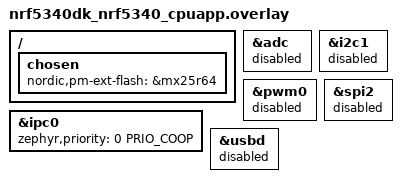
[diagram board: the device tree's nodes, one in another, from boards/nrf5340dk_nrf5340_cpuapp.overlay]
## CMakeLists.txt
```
#
# Copyright (c) 2023 Nordic Semiconductor ASA
#
# SPDX-License-Identifier: LicenseRef-Nordic-5-Clause
#

cmake_minimum_required(VERSION 3.20.0)

find_package(Zephyr HINTS $ENV{ZEPHYR_BASE})

project(matter-bridge)

# Enable GNU STD support.
include(${ZEPHYR_CONNECTEDHOMEIP_MODULE_DIR}/config/nrfconnect/app/enable-gnu-std.cmake)

# NORDIC SDK APP START

# Include all source files that are located in the Matter common directory.
include(${ZEPHYR_NRF_MODULE_DIR}/samples/matter/common/cmake/source_common.cmake)

# Include Data Model utils
include(${ZEPHYR_NRF_MODULE_DIR}/samples/matter/common/cmake/data_model.cmake)

include(${ZEPHYR_NRF_MODULE_DIR}/samples/matter/common/cmake/zap_helpers.cmake)
ncs_get_zap_parent_dir(ZAP_PARENT_DIR)

target_include_directories(app PRIVATE
    src
    src/bridged_device_types
    ${ZAP_PARENT_DIR}
    ${ZEPHYR_NRF_MODULE_DIR}/samples/matter/common/src/bridge/
    ${ZEPHYR_NRF_MODULE_DIR}/samples/matter/common/src/bridge/util
)

target_sources(app PRIVATE
    src/app_task.cpp
    src/main.cpp
    src/bridge_shell.cpp
    src/zcl_callbacks.cpp
    ${ZEPHYR_NRF_MODULE_DIR}/samples/matter/common/src/bridge/bridge_manager.cpp
    ${ZEPHYR_NRF_MODULE_DIR}/samples/matter/common/src/bridge/matter_bridged_device.cpp
    ${ZEPHYR_NRF_MODULE_DIR}/samples/matter/common/src/bridge/bridge_storage_manager.cpp
    ${ZEPHYR_NRF_MODULE_DIR}/samples/matter/common/src/bridge/bridged_device_data_provider.cpp
    ${ZEPHYR_NRF_MODULE_DIR}/samples/matter/common/src/binding/binding_handler.cpp
)

if(CONFIG_BRIDGED_DEVICE_BT)
    target_sources(app PRIVATE
         ${ZEPHYR_NRF_MODULE_DIR}/samples/matter/common/src/bridge/ble_connectivity_manager.cpp
        src/ble_providers/ble_bridged_device_factory.cpp
    )
    target_include_directories(app PRIVATE src/ble_providers)

if(CONFIG_BRIDGE_ONOFF_LIGHT_BRIDGED_DEVICE AND (CONFIG_BRIDGE_GENERIC_SWITCH_BRIDGED_DEVICE OR CONFIG_BRIDGE_ONOFF_LIGHT_SWITCH_BRIDGED_DEVICE))
    target_sources(app PRIVATE
        src/bridged_device_types/onoff_light.cpp
        src/ble_providers/ble_lbs_data_provider.cpp
    )

if(CONFIG_BRIDGE_GENERIC_SWITCH_BRIDGED_DEVICE)
    target_sources(app PRIVATE src/bridged_device_types/generic_switch.cpp)
endif()

if(CONFIG_BRIDGE_ONOFF_LIGHT_SWITCH_BRIDGED_DEVICE)
    target_sources(app PRIVATE
        src/bridged_device_types/onoff_light_switch.cpp
    )
endif()

endif() # CONFIG_BRIDGE_ONOFF_LIGHT_BRIDGED_DEVICE AND (CONFIG_BRIDGE_GENERIC_SWITCH_BRIDGED_DEVICE OR CONFIG_BRIDGE_ONOFF_LIGHT_SWITCH_BRIDGED_DEVICE)

if(CONFIG_BRIDGE_HUMIDITY_SENSOR_BRIDGED_DEVICE)
    target_sources(app PRIVATE
        src/bridged_device_types/humidity_sensor.cpp
    )
endif() # CONFIG_BRIDGE_HUMIDITY_SENSOR_BRIDGED_DEVICE

if(CONFIG_BRIDGE_TEMPERATURE_SENSOR_BRIDGED_DEVICE)
    target_sources(app PRIVATE
        src/bridged_device_types/temperature_sensor.cpp
    )
endif() # CONFIG_BRIDGE_TEMPERATURE_SENSOR_BRIDGED_DEVICE

# Assume it makes no sense to support BLE environmental sensor without all Matter counterparts
if(CONFIG_BRIDGE_TEMPERATURE_SENSOR_BRIDGED_DEVICE AND CONFIG_BRIDGE_HUMIDITY_SENSOR_BRIDGED_DEVICE)
    target_sources(app PRIVATE
        src/ble_providers/ble_environmental_data_provider.cpp
    )
endif() # CONFIG_BRIDGE_TEMPERATURE_SENSOR_BRIDGED_DEVICE AND CONFIG_BRIDGE_HUMIDITY_SENSOR_BRIDGED_DEVICE

else()
    target_sources(app PRIVATE
        src/simulated_providers/simulated_bridged_device_factory.cpp
    )
    target_include_directories(app PRIVATE src/simulated_providers)

if(CONFIG_BRIDGE_ONOFF_LIGHT_BRIDGED_DEVICE AND (CONFIG_BRIDGE_GENERIC_SWITCH_BRIDGED_DEVICE OR CONFIG_BRIDGE_ONOFF_LIGHT_SWITCH_BRIDGED_DEVICE))
    target_sources(app PRIVATE
        src/bridged_device_types/onoff_light.cpp
        src/simulated_providers/simulated_onoff_light_data_provider.cpp
    )

if(CONFIG_BRIDGE_GENERIC_SWITCH_BRIDGED_DEVICE)
    target_sources(app PRIVATE
        src/bridged_device_types/generic_switch.cpp
        src/simulated_providers/simulated_generic_switch_data_provider.cpp
    )
endif()

if(CONFIG_BRIDGE_ONOFF_LIGHT_SWITCH_BRIDGED_DEVICE)
    target_sources(app PRIVATE
        src/bridged_device_types/onoff_light_switch.cpp
        src/simulated_providers/simulated_onoff_light_switch_data_provider.cpp
    )
endif()

endif() # CONFIG_BRIDGE_ONOFF_LIGHT_BRIDGED_DEVICE AND (CONFIG_BRIDGE_GENERIC_SWITCH_BRIDGED_DEVICE OR CONFIG_BRIDGE_ONOFF_LIGHT_SWITCH_BRIDGED_DEVICE))

if(CONFIG_BRIDGE_TEMPERATURE_SENSOR_BRIDGED_DEVICE)
    target_sources(app PRIVATE
            src/bridged_device_types/temperature_sensor.cpp
            src/simulated_providers/simulated_temperature_sensor_data_provider.cpp
    )
endif() # CONFIG_BRIDGE_TEMPERATURE_SENSOR_BRIDGED_DEVICE

if(CONFIG_BRIDGE_HUMIDITY_SENSOR_BRIDGED_DEVICE)
    target_sources(app PRIVATE
        src/bridged_device_types/humidity_sensor.cpp
        src/simulated_providers/simulated_humidity_sensor_data_provider.cpp
    )
endif() # CONFIG_BRIDGE_HUMIDITY_SENSOR_BRIDGED_DEVICE

endif() # CONFIG_BRIDGED_DEVICE_BT

ncs_configure_data_model()
# NORDIC SDK APP END
```

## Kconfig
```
#
# Copyright (c) 2023 Nordic Semiconductor
#
# SPDX-License-Identifier: LicenseRef-Nordic-5-Clause
#
mainmenu "Matter nRF Connect Bridge Example Application"

config BRIDGE_ONOFF_LIGHT_BRIDGED_DEVICE
	bool "Support for OnOff Light bridged device"
	default y

config BRIDGE_TEMPERATURE_SENSOR_BRIDGED_DEVICE
	bool "Support for Temperature Sensor bridged device"
	default y

config BRIDGE_HUMIDITY_SENSOR_BRIDGED_DEVICE
	bool "Support for Humidity Sensor bridged device"
	default y

choice BRIDGE_SWITCH_BRIDGED_DEVICE
	prompt "Bridged device switch implementation"
	default BRIDGE_GENERIC_SWITCH_BRIDGED_DEVICE

config BRIDGE_GENERIC_SWITCH_BRIDGED_DEVICE
	bool "Support for Generic Switch bridged device"

config BRIDGE_ONOFF_LIGHT_SWITCH_BRIDGED_DEVICE
	bool "Support for OnOff Light Switch bridged device"

endchoice

choice BRIDGED_DEVICE_IMPLEMENTATION
	prompt "Bridged Device implementation"
	default BRIDGED_DEVICE_SIMULATED

	config BRIDGED_DEVICE_SIMULATED
		bool "Simulated Bridged Device"
		help
		  Enables using simulated bridged devices that do not perform
		  real operations, but emulate exemplary data to imitate the real
		  device behavior.

	config BRIDGED_DEVICE_BT
		bool "Bluetooth LE Bridged Device"
		help
		  Enables using real bridged devices that communicate with the Matter bridge device
		  over Bluetooth LE.

endchoice

if BRIDGED_DEVICE_SIMULATED

choice BRIDGED_DEVICE_SIMULATED_ONOFF_IMPLEMENTATION
	prompt "Simulated bridged onoff device implementation"
	default BRIDGED_DEVICE_SIMULATED_ONOFF_SHELL

	config BRIDGED_DEVICE_SIMULATED_ONOFF_AUTOMATIC
		bool "Automatically simulated bridged onoff device"
		help
		  Enables using simulated bridged onoff device that
		  automatically changes its state periodically.

	config BRIDGED_DEVICE_SIMULATED_ONOFF_SHELL
		bool "Shell controlled simulated bridged onoff device"
		help
		  Enables using simulated bridged onoff device that is
		  controlled by shell commands.

endchoice

endif

if BRIDGED_DEVICE_BT

config BT_CENTRAL
	default y

config BT_SCAN
	default y

# Configure how many Bluetooth LE devices the Matter bridge can support (the final number is given value - 1, as 1 connection is used for the Matter Bluetooth LE service).
config BT_MAX_CONN
	default 10

config BT_SCAN_FILTER_ENABLE
	default y

# Configure how many Bluetooth LE service UUIDs the Matter bridge can scan.
config BT_SCAN_UUID_CNT
	default 2

config BT_SCAN_ADDRESS_CNT
	default 1

config BT_GATT_CLIENT
	default y

config BT_GATT_DM
	default y

config BT_EXT_ADV
	default y

config BT_SMP
	default y

if BT_SMP

config BT_SETTINGS
	default y

# Configure how many Bluetooth LE devices will be paired with Matter bridge. Assuming it will be only bridged devices, it should be set to BT_MAX_CONN - 1.
config BT_MAX_PAIRED
	default 9

# Use two Bluetooth LE identities. The first one is used by the peripheral for Matter service advertising purposes, and the other is used by the Matter bridge central.
config BT_ID_MAX
	default 2

config BT_EXT_ADV_LEGACY_SUPPORT
	default y

endif

config BRIDGE_BLE_DEVICE_POLLING_INTERVAL
	int "BLE humidity measurement readout polling interval in ms"
	default 3000

endif

if BRIDGE_TEMPERATURE_SENSOR_BRIDGED_DEVICE

config BRIDGE_TEMPERATURE_SENSOR_MIN_MEASURED_VALUE
	int "Default minimum measured value allowed by the bridged temperature sensor device"
	default -20

config BRIDGE_TEMPERATURE_SENSOR_MAX_MEASURED_VALUE
	int "Default maximum measured value allowed by the bridged temperature sensor device"
	default 60

endif

if BRIDGE_HUMIDITY_SENSOR_BRIDGED_DEVICE

config BRIDGE_HUMIDITY_SENSOR_MIN_MEASURED_VALUE
	int "Default minimum measured value allowed by the bridged humidity sensor device"
	default 0

config BRIDGE_HUMIDITY_SENSOR_MAX_MEASURED_VALUE
	int "Default maximum measured value allowed by the bridged humidity sensor device"
	default 100

endif

# Enable Read Client functionality for all build configurations.
config CHIP_ENABLE_READ_CLIENT
	default y

config NCS_SAMPLE_MATTER_PERSISTENT_STORAGE
	default y

config BRIDGE_SMART_PLUG_SUPPORT
	bool "Enables additional endpoint implementing Matter smart plug functionality"
	default n

# Sample configuration used for Thread networking
if OPENTHREAD

choice OPENTHREAD_NORDIC_LIBRARY_CONFIGURATION
	default OPENTHREAD_NORDIC_LIBRARY_FTD
endchoice

choice OPENTHREAD_DEVICE_TYPE
	default OPENTHREAD_FTD
endchoice

endif # OPENTHREAD

# Dummy Kconfig just to select experimental for some of the configurations.
config BRIDGE_EXPERIMENTAL
	bool
	default y if OPENTHREAD || BRIDGE_SMART_PLUG_SUPPORT
	select EXPERIMENTAL

source "${ZEPHYR_CONNECTEDHOMEIP_MODULE_DIR}/config/nrfconnect/chip-module/Kconfig.features"
source "${ZEPHYR_CONNECTEDHOMEIP_MODULE_DIR}/config/nrfconnect/chip-module/Kconfig.defaults"
source "${ZEPHYR_NRF_MODULE_DIR}/samples/matter/common/src/bridge/Kconfig"
source "${ZEPHYR_NRF_MODULE_DIR}/samples/matter/common/src/Kconfig"
source "Kconfig.zephyr"
```

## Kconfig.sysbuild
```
#
# Copyright (c) 2023 Nordic Semiconductor ASA
#
# SPDX-License-Identifier: LicenseRef-Nordic-5-Clause
#

config WIFI_NRF70
	default y if BOARD_NRF7002DK

#### Radio core
config NRF_DEFAULT_IPC_RADIO
	default y

# Enable Bluetooth serialization to network core
config NETCORE_IPC_RADIO_BT_HCI_IPC
	default y

#### Bootloader
choice BOOTLOADER
	default BOOTLOADER_MCUBOOT
endchoice

# Enable IEEE802.15.4 serialization to network core
# This config automatically pulls in the `overlay-802154.conf` in the ipc_radio image
config NETCORE_IPC_RADIO_IEEE802154
	default y if SOC_SERIES_NRF53X && !WIFI_NRF70

if BOOTLOADER_MCUBOOT

#### DFU multi-image support
config DFU_MULTI_IMAGE_PACKAGE_BUILD
	default y

config DFU_MULTI_IMAGE_PACKAGE_APP
	default y

config PM_EXTERNAL_FLASH_MCUBOOT_SECONDARY
	default y

#### DFU network core configuration
if SOC_SERIES_NRF53X

config MCUBOOT_UPDATEABLE_IMAGES
	default 3 if (BOARD_NRF5340DK_NRF5340_CPUAPP && WIFI_NRF70) #### Support for WiFi patch on external flash memory.
	default 2

choice MCUBOOT_MODE
	default MCUBOOT_MODE_OVERWRITE_ONLY
endchoice

choice BOOT_SIGNATURE_TYPE
	default BOOT_SIGNATURE_TYPE_RSA
endchoice

config SECURE_BOOT_NETCORE
	default y

config NETCORE_APP_UPDATE
	default y

config DFU_MULTI_IMAGE_PACKAGE_NET
	default y

endif # SOC_SERIES_NRF53X
endif # BOOTLOADER_MCUBOOT

#### Enable generating factory data
config MATTER_FACTORY_DATA_GENERATE
	default y

source "share/sysbuild/Kconfig"
```

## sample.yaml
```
sample:
  description: Matter Bridge
  name: Matter Bridge application
tests:
  applications.matter_bridge.release:
    sysbuild: true
    build_only: true
    extra_args:
      - FILE_SUFFIX=release
      - CONFIG_BRIDGE_GENERIC_SWITCH_BRIDGED_DEVICE=n
      - CONFIG_BRIDGE_ONOFF_LIGHT_SWITCH_BRIDGED_DEVICE=y
    integration_platforms:
      - nrf7002dk/nrf5340/cpuapp
      - nrf5340dk/nrf5340/cpuapp
    platform_allow:
      - nrf7002dk/nrf5340/cpuapp
      - nrf5340dk/nrf5340/cpuapp
    tags:
      - sysbuild
      - ci_applications_matter
  applications.matter_bridge.debug:
    sysbuild: true
    build_only: true
    extra_args:
      - CONFIG_BRIDGE_GENERIC_SWITCH_BRIDGED_DEVICE=n
      - CONFIG_BRIDGE_ONOFF_LIGHT_SWITCH_BRIDGED_DEVICE=y
    integration_platforms:
      - nrf7002dk/nrf5340/cpuapp
      - nrf5340dk/nrf5340/cpuapp
    platform_allow:
      - nrf7002dk/nrf5340/cpuapp
      - nrf5340dk/nrf5340/cpuapp
    tags:
      - sysbuild
      - ci_applications_matter
  applications.matter_bridge.br_ble:
    sysbuild: true
    build_only: true
    extra_args:
      - CONFIG_BRIDGED_DEVICE_BT=y
      - CONFIG_BRIDGE_GENERIC_SWITCH_BRIDGED_DEVICE=n
      - CONFIG_BRIDGE_ONOFF_LIGHT_SWITCH_BRIDGED_DEVICE=y
    integration_platforms:
      - nrf7002dk/nrf5340/cpuapp
      - nrf5340dk/nrf5340/cpuapp
    platform_allow:
      - nrf7002dk/nrf5340/cpuapp
      - nrf5340dk/nrf5340/cpuapp
    tags:
      - sysbuild
      - ci_applications_matter
  applications.matter_bridge.release.br_ble:
    sysbuild: true
    build_only: true
    extra_args:
      - FILE_SUFFIX=release
      - CONFIG_BRIDGED_DEVICE_BT=y
      - CONFIG_BRIDGE_GENERIC_SWITCH_BRIDGED_DEVICE=n
      - CONFIG_BRIDGE_ONOFF_LIGHT_SWITCH_BRIDGED_DEVICE=y
    integration_platforms:
      - nrf7002dk/nrf5340/cpuapp
      - nrf5340dk/nrf5340/cpuapp
    platform_allow:
      - nrf7002dk/nrf5340/cpuapp
      - nrf5340dk/nrf5340/cpuapp
    tags:
      - sysbuild
      - ci_applications_matter
  applications.matter_bridge.br_ble.smp_dfu:
    sysbuild: true
    build_only: true
    extra_args:
      - CONFIG_CHIP_DFU_OVER_BT_SMP=y
      - CONFIG_BRIDGED_DEVICE_BT=y
      - CONFIG_BRIDGE_GENERIC_SWITCH_BRIDGED_DEVICE=n
      - CONFIG_BRIDGE_ONOFF_LIGHT_SWITCH_BRIDGED_DEVICE=y
    integration_platforms:
      - nrf7002dk/nrf5340/cpuapp
    platform_allow: nrf7002dk/nrf5340/cpuapp
    tags:
      - sysbuild
      - ci_applications_matter
  applications.matter_bridge.nrf5340.wifi:
    sysbuild: true
    build_only: true
    extra_args:
      - matter_bridge_SHIELD=nrf7002ek
      - SB_CONFIG_WIFI_PATCHES_EXT_FLASH_STORE=y
      - mcuboot_CONFIG_UPDATEABLE_IMAGE_NUMBER=3
      - SB_CONFIG_WIFI_NRF70=y
      - SB_CONFIG_DFU_MULTI_IMAGE_PACKAGE_WIFI_FW_PATCH=y
      - CONFIG_CHIP_DFU_OVER_BT_SMP=y
      - FILE_SUFFIX=nrf70ek
    integration_platforms:
      - nrf5340dk/nrf5340/cpuapp
    platform_allow: nrf5340dk/nrf5340/cpuapp
    tags:
      - sysbuild
      - ci_applications_matter
  applications.matter_bridge.br_ble.memory_profiling:
    sysbuild: true
    build_only: true
    extra_args:
      - CONFIG_BRIDGE_GENERIC_SWITCH_BRIDGED_DEVICE=n
      - CONFIG_BRIDGE_ONOFF_LIGHT_SWITCH_BRIDGED_DEVICE=y
      - CONFIG_CHIP_MEMORY_PROFILING=y
      - CONFIG_BRIDGED_DEVICE_BT=y
      - CONFIG_BRIDGE_MIGRATE_VERSION_1=n
      - CONFIG_WIFI_NM_WPA_SUPPLICANT_WPA3=n
    integration_platforms:
      - nrf5340dk/nrf5340/cpuapp
    platform_allow:
      - nrf5340dk/nrf5340/cpuapp
    tags:
      - sysbuild
      - ci_applications_matter
  applications.matter_bridge.memory_profiling:
    sysbuild: true
    build_only: true
    extra_args:
      - CONFIG_BRIDGE_GENERIC_SWITCH_BRIDGED_DEVICE=n
      - CONFIG_BRIDGE_ONOFF_LIGHT_SWITCH_BRIDGED_DEVICE=y
      - CONFIG_CHIP_MEMORY_PROFILING=y
    integration_platforms:
      - nrf7002dk/nrf5340/cpuapp
    platform_allow:
      - nrf7002dk/nrf5340/cpuapp
    tags:
      - sysbuild
      - ci_applications_matter
  applications.matter_bridge.smart_plug:
    sysbuild: true
    build_only: true
    extra_args:
      - matter_bridge_SNIPPET=onoff_plug
    integration_platforms:
      - nrf5340dk/nrf5340/cpuapp
    platform_allow: nrf5340dk/nrf5340/cpuapp
    tags:
      - sysbuild
      - ci_applications_matter
```

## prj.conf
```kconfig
#
# Copyright (c) 2023 Nordic Semiconductor ASA
#
# SPDX-License-Identifier: LicenseRef-Nordic-5-Clause
#

# This sample uses Kconfig.defaults to set options common for all
# samples. This file should contain only options specific for this sample
# or overrides of default values.

# Enable CHIP
CONFIG_CHIP=y
CONFIG_CHIP_PROJECT_CONFIG="src/chip_project_config.h"

# Configure ZAP file name
CONFIG_NCS_SAMPLE_MATTER_ZAP_FILE_PATH="${APPLICATION_CONFIG_DIR}/src/default_zap/bridge.zap"

# 32770 == 0x8002 (example bridge)
CONFIG_CHIP_DEVICE_PRODUCT_ID=32770
CONFIG_STD_CPP17=y

# Enable Matter pairing automatically on application start.
CONFIG_CHIP_ENABLE_PAIRING_AUTOSTART=y

# Enable Matter extended announcement and increase duration to 1 hour.
CONFIG_CHIP_BLE_EXT_ADVERTISING=y
CONFIG_CHIP_BLE_ADVERTISING_DURATION=60

# Add support for LEDs and buttons on Nordic development kits
CONFIG_DK_LIBRARY=y

# Bluetooth Low Energy configuration
CONFIG_BT_DEVICE_NAME="MatterBridge"

# Other settings
CONFIG_THREAD_NAME=y
CONFIG_MPU_STACK_GUARD=y
CONFIG_RESET_ON_FATAL_ERROR=n
CONFIG_CHIP_LIB_SHELL=y
CONFIG_NCS_SAMPLE_MATTER_TEST_SHELL=y

# Reduce assert verbosity to save flash space.
CONFIG_ASSERT_NO_FILE_INFO=y

# Disable NFC onboarding
CONFIG_CHIP_NFC_ONBOARDING_PAYLOAD=n

# Reduce application size
CONFIG_USE_SEGGER_RTT=n

# Enable Factory Data feature
CONFIG_CHIP_FACTORY_DATA=y
CONFIG_CHIP_FACTORY_DATA_BUILD=y

# Enable LTO to decrease the flash usage.
CONFIG_LTO=y
CONFIG_ISR_TABLES_LOCAL_DECLARATION=y

# Increase heap size to accommodate the memory required for additional bridged devices.
CONFIG_CHIP_MALLOC_SYS_HEAP_SIZE=16384
```

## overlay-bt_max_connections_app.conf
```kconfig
#
# Copyright (c) 2023 Nordic Semiconductor ASA
#
# SPDX-License-Identifier: LicenseRef-Nordic-5-Clause
#

# Set 20 BLE connections, as it is an upper limit supported by the Soft Device Controller.
CONFIG_BT_MAX_CONN=20

# Set buffer sizes in a consistent way with the ones used by the network core.
CONFIG_BT_BUF_ACL_RX_SIZE=84
CONFIG_BT_BUF_ACL_TX_SIZE=84

# Set MTU size to fit in the single buffer and avoid fragmentation (BUF_SIZE = MTU_SIZE + 4 B of L2CAP header).
CONFIG_BT_L2CAP_TX_MTU=80

# Set max number of bridged BLE devices, which is CONFIG_BT_MAX_CONN-1, as 1 connection is reserved for Matter.
CONFIG_BRIDGE_MAX_BRIDGED_DEVICES_NUMBER=19
CONFIG_BT_MAX_PAIRED=19

# Assume that every bridged device uses only 1 endpoint, however it can be increased if specific use case requires it.
CONFIG_BRIDGE_MAX_DYNAMIC_ENDPOINTS_NUMBER=19
```

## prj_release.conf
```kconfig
#
# Copyright (c) 2023 Nordic Semiconductor ASA
#
# SPDX-License-Identifier: LicenseRef-Nordic-5-Clause
#

# This sample uses Kconfig.defaults to set options common for all
# samples. This file should contain only options specific for this sample
# or overrides of default values.

# Enable CHIP
CONFIG_CHIP=y
CONFIG_CHIP_PROJECT_CONFIG="src/chip_project_config.h"

# Configure ZAP file name
CONFIG_NCS_SAMPLE_MATTER_ZAP_FILE_PATH="${APPLICATION_CONFIG_DIR}/src/default_zap/bridge.zap"

# 32770 == 0x8002 (example bridge)
CONFIG_CHIP_DEVICE_PRODUCT_ID=32770
CONFIG_STD_CPP17=y

# Enable Matter pairing automatically on application start.
CONFIG_CHIP_ENABLE_PAIRING_AUTOSTART=y

# Enable Matter extended announcement and increase duration to 1 hour.
CONFIG_CHIP_BLE_EXT_ADVERTISING=y
CONFIG_CHIP_BLE_ADVERTISING_DURATION=60

# Add support for LEDs and buttons on Nordic development kits
CONFIG_DK_LIBRARY=y

# Bluetooth Low Energy configuration
CONFIG_BT_DEVICE_NAME="MatterBridge"

# Enable system reset on fatal error
CONFIG_RESET_ON_FATAL_ERROR=y

# Disable all debug features
CONFIG_USE_SEGGER_RTT=n
CONFIG_OPENTHREAD_SHELL=n
CONFIG_LOG=n
CONFIG_LOG_MODE_MINIMAL=n
CONFIG_ASSERT_VERBOSE=n
CONFIG_ASSERT_NO_FILE_INFO=y
CONFIG_PRINTK=n
CONFIG_PRINTK_SYNC=n
CONFIG_THREAD_NAME=n
CONFIG_BOOT_BANNER=n

# Disable NFC onboarding
CONFIG_CHIP_NFC_ONBOARDING_PAYLOAD=n

# Enable Factory Data feature
CONFIG_CHIP_FACTORY_DATA=y
CONFIG_CHIP_FACTORY_DATA_BUILD=y

# Enable the Read Client for binding purposes
CONFIG_CHIP_ENABLE_READ_CLIENT=y

# Enable Watchdog
CONFIG_NCS_SAMPLE_MATTER_WATCHDOG=y

# Enable LTO to decrease the flash usage.
CONFIG_LTO=y
CONFIG_ISR_TABLES_LOCAL_DECLARATION=y

# Increase heap size to accommodate the memory required for additional bridged devices.
CONFIG_CHIP_MALLOC_SYS_HEAP_SIZE=16384
```

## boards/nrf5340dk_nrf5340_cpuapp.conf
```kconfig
#
# Copyright (c) 2023 Nordic Semiconductor ASA
#
# SPDX-License-Identifier: LicenseRef-Nordic-5-Clause
#

# Set 10 BLE connections, as it is an upper limit supported caused by RAM usage due to using Thread and BLE at same time.
CONFIG_BT_MAX_CONN=10

# Set buffer sizes in a consistent way with the ones used by the network core.
#id if oncomment it there is an error that rx buffer is out of range (minimal value is 69)
CONFIG_BT_BUF_ACL_RX_SIZE=69
CONFIG_BT_BUF_ACL_TX_SIZE=69

# Set MTU size to fit in the single buffer and avoid fragmentation (BUF_SIZE = MTU_SIZE + 4 B of L2CAP header).
CONFIG_BT_L2CAP_TX_MTU=65

# Set max number of bridged BLE devices, which is CONFIG_BT_MAX_CONN-1, as 1 connection is reserved for Matter.
CONFIG_BRIDGE_MAX_BRIDGED_DEVICES_NUMBER=9
CONFIG_BT_MAX_PAIRED=9

# Assume that every bridged device uses 2 endpoints, however it can be increased if specific use case requires it.
CONFIG_BRIDGE_MAX_DYNAMIC_ENDPOINTS_NUMBER=18
# 15.4 RX buffers were decreased to save RAM
CONFIG_NRF_802154_RX_BUFFERS=14
```

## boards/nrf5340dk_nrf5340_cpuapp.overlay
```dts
/*
 * Copyright (c) 2024 Nordic Semiconductor ASA
 *
 * SPDX-License-Identifier: LicenseRef-Nordic-5-Clause
 */

#include <zephyr/dt-bindings/ipc_service/static_vrings.h>

/ {
	chosen {
		nordic,pm-ext-flash = &mx25r64;
	};
};

/* Set IPC thread priority to the highest value to not collide with other threads. */
&ipc0 {
	zephyr,priority = <0 PRIO_COOP>;
};

/* Disable unused peripherals to reduce power consumption */
&adc {
	status = "disabled";
};
&i2c1 {
	status = "disabled";
};
&pwm0 {
	status = "disabled";
};
&spi2 {
	status = "disabled";
};
&usbd {
	status = "disabled";
};
```

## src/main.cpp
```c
/*
 * Copyright (c) 2023 Nordic Semiconductor ASA
 *
 * SPDX-License-Identifier: LicenseRef-Nordic-5-Clause
 */

#include "app_task.h"

#include <zephyr/logging/log.h>

LOG_MODULE_REGISTER(app, CONFIG_CHIP_APP_LOG_LEVEL);

int main()
{
	CHIP_ERROR err = AppTask::Instance().StartApp();

	LOG_ERR("Exited with code %" CHIP_ERROR_FORMAT, err.Format());
	return err == CHIP_NO_ERROR ? EXIT_SUCCESS : EXIT_FAILURE;
}
```

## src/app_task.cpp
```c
/*
 * Copyright (c) 2023 Nordic Semiconductor ASA
 *
 * SPDX-License-Identifier: LicenseRef-Nordic-5-Clause
 */

#include "app_task.h"

#ifdef CONFIG_BRIDGED_DEVICE_BT
#include "ble_bridged_device_factory.h"
#else
#include "simulated_bridged_device_factory.h"
#endif /* CONFIG_BRIDGED_DEVICE_BT */

#include "app/matter_init.h"
#include "app/task_executor.h"
#include "board/board.h"
#include "bridge/bridge_manager.h"
#include "bridge/bridge_storage_manager.h"

#ifdef CONFIG_BRIDGED_DEVICE_BT
#include "bridge/ble_connectivity_manager.h"
#endif

#include <app-common/zap-generated/attributes/Accessors.h>
#include <app-common/zap-generated/ids/Attributes.h>
#include <app-common/zap-generated/ids/Clusters.h>
#include <setup_payload/OnboardingCodesUtil.h>

#ifdef CONFIG_BRIDGED_DEVICE_BT
#include <bluetooth/services/lbs.h>
#endif /* CONFIG_BRIDGED_DEVICE_BT */
#include <zephyr/logging/log.h>

#ifdef CONFIG_BRIDGE_SMART_PLUG_SUPPORT
#define APPLICATION_BUTTON_MASK DK_BTN2_MSK
#endif /* CONFIG_BRIDGE_SMART_PLUG_SUPPORT */

LOG_MODULE_DECLARE(app, CONFIG_CHIP_APP_LOG_LEVEL);

using namespace ::chip;
using namespace ::chip::app;
using namespace ::chip::DeviceLayer;
namespace
{

#ifdef CONFIG_BRIDGED_DEVICE_BT
static const bt_uuid *sUuidLbs = BT_UUID_LBS;
static const bt_uuid *sUuidEs = BT_UUID_ESS;
static const bt_uuid *sUuidServices[] = { sUuidLbs, sUuidEs };
static constexpr uint8_t kUuidServicesNumber = ARRAY_SIZE(sUuidServices);
/**
 * @brief Blink rates for indication the BLE Connectivity Manager state.
 *
 */
constexpr static uint32_t kPairingBlinkRate{ 100 };
constexpr static uint32_t kScanningBlinkRate_ms{ 300 };
constexpr static uint32_t kLostBlinkRate_ms{ 1000 };
#ifndef CONFIG_BRIDGE_SMART_PLUG_SUPPORT
void BLEStateChangeCallback(Nrf::BLEConnectivityManager::State state)
{
	switch (state) {
	case Nrf::BLEConnectivityManager::State::Connected:
		Nrf::PostTask([] { Nrf::GetBoard().GetLED(Nrf::DeviceLeds::LED2).Set(true); });
		break;
	case Nrf::BLEConnectivityManager::State::Scanning:
		Nrf::PostTask([] {
			Nrf::GetBoard()
				.GetLED(Nrf::DeviceLeds::LED2)
				.Blink(kScanningBlinkRate_ms, kScanningBlinkRate_ms);
		});
		break;
	case Nrf::BLEConnectivityManager::State::LostDevice:
		Nrf::PostTask([] {
			Nrf::GetBoard().GetLED(Nrf::DeviceLeds::LED2).Blink(kLostBlinkRate_ms, kLostBlinkRate_ms);
		});
		break;
	case Nrf::BLEConnectivityManager::State::Pairing:
		Nrf::PostTask([] {
			Nrf::GetBoard().GetLED(Nrf::DeviceLeds::LED2).Blink(kPairingBlinkRate, kPairingBlinkRate);
		});
		break;
	default:
		Nrf::PostTask([] { Nrf::GetBoard().GetLED(Nrf::DeviceLeds::LED2).Set(false); });
	}
}
#endif /* CONFIG_BRIDGE_SMART_PLUG_SUPPORT */

#endif /* CONFIG_BRIDGED_DEVICE_BT */

#ifndef CONFIG_CHIP_FACTORY_RESET_ERASE_SETTINGS
void AppFactoryResetHandler(const ChipDeviceEvent *event, intptr_t /* unused */)
{
	switch (event->Type) {
	case DeviceEventType::kFactoryReset:
		Nrf::BridgeStorageManager::Instance().FactoryReset();
		break;
	default:
		break;
	}
}
#endif

} /* namespace */

CHIP_ERROR AppTask::RestoreBridgedDevices()
{
	uint8_t count;
	uint8_t indexes[Nrf::BridgeManager::kMaxBridgedDevices] = { 0 };
	size_t indexesCount = 0;

	if (!Nrf::BridgeStorageManager::Instance().LoadBridgedDevicesCount(count)) {
		LOG_INF("No bridged devices to load from the storage.");
		return CHIP_NO_ERROR;
	}

	if (!Nrf::BridgeStorageManager::Instance().LoadBridgedDevicesIndexes(
		    indexes, Nrf::BridgeManager::kMaxBridgedDevices, indexesCount)) {
		return CHIP_NO_ERROR;
	}

	/* Load all devices based on the read count number. */
	for (size_t i = 0; i < indexesCount; i++) {
		Nrf::BridgeStorageManager::BridgedDevice device;
#ifdef CONFIG_BRIDGED_DEVICE_BT
		bt_addr_le_t btAddr;
		device.mUserData = reinterpret_cast<uint8_t *>(&btAddr);
		device.mUserDataSize = sizeof(btAddr);
#endif

		if (!Nrf::BridgeStorageManager::Instance().LoadBridgedDevice(device, indexes[i])) {
			return CHIP_ERROR_NOT_FOUND;
		}

		LOG_INF("Loaded bridged device on endpoint id %d from the storage", device.mEndpointId);

#ifdef CONFIG_BRIDGED_DEVICE_BT
		BleBridgedDeviceFactory::CreateDevice(device.mDeviceType, btAddr, device.mUniqueID, device.mNodeLabel,
						      indexes[i], device.mEndpointId);
#else
		SimulatedBridgedDeviceFactory::CreateDevice(device.mDeviceType, device.mUniqueID, device.mNodeLabel,
							    chip::Optional<uint8_t>(indexes[i]),
							    chip::Optional<uint16_t>(device.mEndpointId));
#endif
	}
	return CHIP_NO_ERROR;
}
#ifdef CONFIG_BRIDGE_SMART_PLUG_SUPPORT
void AppTask::SmartplugOnOffEventHandler()
{
	SystemLayer().ScheduleLambda([] {
		bool newState = !Nrf::GetBoard().GetLED(Nrf::DeviceLeds::LED2).GetState();
		Protocols::InteractionModel::Status status =
			Clusters::OnOff::Attributes::OnOff::Set(kSmartplugEndpointId, newState);
		if (status != Protocols::InteractionModel::Status::Success) {
			LOG_ERR("Updating on/off cluster failed: %x", to_underlying(status));
		}
	});
}

void AppTask::ButtonEventHandler(Nrf::ButtonState state, Nrf::ButtonMask hasChanged)
{
	if ((APPLICATION_BUTTON_MASK & hasChanged) & state) {
		Nrf::PostTask([] { SmartplugOnOffEventHandler(); });
	}
}
#endif /* CONFIG_BRIDGE_SMART_PLUG_SUPPORT */

CHIP_ERROR AppTask::Init()
{
	/* Initialize Matter stack */
	ReturnErrorOnFailure(Nrf::Matter::PrepareServer(Nrf::Matter::InitData{ .mPostServerInitClbk = [] {
#ifdef CONFIG_BRIDGED_DEVICE_BT
#ifndef CONFIG_BRIDGE_SMART_PLUG_SUPPORT
		Nrf::BLEConnectivityManager::Instance().RegisterStateCallback(BLEStateChangeCallback);
#endif /* CONFIG_BRIDGE_SMART_PLUG_SUPPORT */
		/* Initialize BLE Connectivity Manager before the Bridge Manager, as it must be ready to recover
		 * devices loaded from persistent storage during the bridge init. */
		CHIP_ERROR bleInitError =
			Nrf::BLEConnectivityManager::Instance().Init(sUuidServices, kUuidServicesNumber);
		if (bleInitError != CHIP_NO_ERROR) {
			LOG_ERR("BLEConnectivityManager initialization failed");
			return bleInitError;
		}
#endif

		/* Initialize bridge manager */
		CHIP_ERROR bridgeMgrInitError = Nrf::BridgeManager::Instance().Init(RestoreBridgedDevices);
		if (bridgeMgrInitError != CHIP_NO_ERROR) {
			LOG_ERR("BridgeManager initialization failed");
			return bridgeMgrInitError;
		}
		return CHIP_NO_ERROR;
	} }));
#ifdef CONFIG_BRIDGE_SMART_PLUG_SUPPORT
	/* onoff plug part add buttonEventHandler*/
	if (!Nrf::GetBoard().Init(ButtonEventHandler)) {
		LOG_ERR("User interface initialization failed.");
		return CHIP_ERROR_INCORRECT_STATE;
	}
#else
	if (!Nrf::GetBoard().Init()) {
		LOG_ERR("User interface initialization failed.");
		return CHIP_ERROR_INCORRECT_STATE;
	}
#endif
	/* Register Matter event handler that controls the connectivity status LED based on the captured Matter
	 * network state. */
	ReturnErrorOnFailure(Nrf::Matter::RegisterEventHandler(Nrf::Board::DefaultMatterEventHandler, 0));

#ifndef CONFIG_CHIP_FACTORY_RESET_ERASE_SETTINGS
	/* Register factory reset event handler.
	 * With this configuration we have to manually clean up the storage,
	 * as whole settings partition won't be erased.
	 * */
	ReturnErrorOnFailure(Nrf::Matter::RegisterEventHandler(AppFactoryResetHandler, 0));
#endif

	return Nrf::Matter::StartServer();
}

CHIP_ERROR AppTask::StartApp()
{
	ReturnErrorOnFailure(Init());

	while (true) {
		Nrf::DispatchNextTask();
	}

	return CHIP_NO_ERROR;
}
```

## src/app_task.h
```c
/*
 * Copyright (c) 2023 Nordic Semiconductor ASA
 *
 * SPDX-License-Identifier: LicenseRef-Nordic-5-Clause
 */

#pragma once

#include "board/board.h"
#include <platform/CHIPDeviceLayer.h>

class AppTask {
public:
	static AppTask &Instance()
	{
		static AppTask sAppTask;
		return sAppTask;
	};

	CHIP_ERROR StartApp();
#ifdef CONFIG_BRIDGE_SMART_PLUG_SUPPORT
	static constexpr chip::EndpointId kSmartplugEndpointId = 2;
	static void ButtonEventHandler(Nrf::ButtonState state, Nrf::ButtonMask hasChanged);
	static void SmartplugOnOffEventHandler();
#endif /* CONFIG_BRIDGE_SMART_PLUG_SUPPORT */

private:
	CHIP_ERROR Init();

	static CHIP_ERROR RestoreBridgedDevices();
};
```

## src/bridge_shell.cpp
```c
/*
 * Copyright (c) 2023 Nordic Semiconductor ASA
 *
 * SPDX-License-Identifier: LicenseRef-Nordic-5-Clause
 */

#include "bridge_manager.h"
#include "platform/ConfigurationManager.h"

#ifdef CONFIG_BRIDGED_DEVICE_BT
#include "ble_bridged_device_factory.h"
#include "ble_connectivity_manager.h"
#else
#include "simulated_bridged_device_factory.h"
#endif /* CONFIG_BRIDGED_DEVICE_BT */

#include <zephyr/shell/shell.h>

#if defined(CONFIG_BRIDGED_DEVICE_BT) && defined(CONFIG_BT_SMP)
static void BluetoothConnectionSecurityRequest(void *context)
{
	if (!context) {
		return;
	}

	const struct shell *shell = reinterpret_cast<struct shell *>(context);

	shell_fprintf(shell, SHELL_INFO,
		      "----------------------------------------------------------------------------------------\n");
	shell_fprintf(shell, SHELL_INFO,
		      "| Bridged Bluetooth LE device authentication                                           |\n");
	shell_fprintf(shell, SHELL_INFO,
		      "|                                                                                      |\n");
	shell_fprintf(shell, SHELL_INFO,
		      "| Insert pin code displayed by the Bluetooth LE peripheral device                      |\n");
	shell_fprintf(shell, SHELL_INFO,
		      "| to authenticate the pairing operation.                                               |\n");
	shell_fprintf(shell, SHELL_INFO,
		      "|                                                                                      |\n");
	shell_fprintf(shell, SHELL_INFO,
		      "| To do that, use matter_bridge pincode <ble_device_index> <pincode> shell command.    |\n");
	shell_fprintf(shell, SHELL_INFO,
		      "----------------------------------------------------------------------------------------\n");
}
#endif /* CONFIG_BRIDGED_DEVICE_BT && CONFIG_BT_SMP */

static int AddBridgedDeviceHandler(const struct shell *shell, size_t argc, char **argv)
{
	char *nodeLabel = nullptr;
	CHIP_ERROR result = CHIP_NO_ERROR;

	char uniqueID[chip::DeviceLayer::ConfigurationManager::kMaxUniqueIDLength];
	chip::DeviceLayer::ConfigurationMgrImpl().GenerateUniqueId(uniqueID, sizeof(uniqueID));

#if defined(CONFIG_BRIDGED_DEVICE_BT)
	int bleDeviceIndex = strtoul(argv[1], NULL, 0);

	if (argv[2]) {
		nodeLabel = argv[2];
	}

	bt_addr_le_t address;
	if (Nrf::BLEConnectivityManager::Instance().GetScannedDeviceAddress(&address, bleDeviceIndex) !=
	    CHIP_NO_ERROR) {
		shell_fprintf(shell, SHELL_ERROR, "Invalid Bluetooth LE device index.\n");
	} else {
		shell_fprintf(shell, SHELL_ERROR, "Found device address\n");
	}

	uint16_t uuid;
	if (Nrf::BLEConnectivityManager::Instance().GetScannedDeviceUuid(uuid, bleDeviceIndex) != CHIP_NO_ERROR) {
		shell_fprintf(shell, SHELL_ERROR, "Invalid Bluetooth LE device index.\n");
	}

#ifdef CONFIG_BT_SMP
	Nrf::BLEConnectivityManager::ConnectionSecurityRequest request;
	request.mCallback = BluetoothConnectionSecurityRequest;
	request.mContext = const_cast<struct shell *>(shell);
	result = BleBridgedDeviceFactory::CreateDevice(uuid, address, uniqueID, nodeLabel, &request);
#else
	result = BleBridgedDeviceFactory::CreateDevice(uuid, uniqueID, address, nodeLabel);
#endif /* CONFIG_BT_SMP */

#elif defined(CONFIG_BRIDGED_DEVICE_SIMULATED)
	int deviceType = strtoul(argv[1], NULL, 0);

	if (argv[2]) {
		nodeLabel = argv[2];
	}

	result = SimulatedBridgedDeviceFactory::CreateDevice(deviceType, uniqueID, nodeLabel);

#else
	return -ENOTSUP;

#endif /* CONFIG_BRIDGED_DEVICE_BT */

	if (result == CHIP_NO_ERROR) {
		shell_fprintf(shell, SHELL_INFO, "Done\n");
	} else if (result == CHIP_ERROR_INCORRECT_STATE) {
		shell_fprintf(shell, SHELL_INFO, "Device is already added\n");
	} else {
		shell_fprintf(shell, SHELL_ERROR, "Device add failed\n");
	}

	return 0;
}

static int RemoveBridgedDeviceHandler(const struct shell *shell, size_t argc, char **argv)
{
	int endpointId = strtoul(argv[1], NULL, 0);

#if defined(CONFIG_BRIDGED_DEVICE_BT)
	if (CHIP_NO_ERROR == BleBridgedDeviceFactory::RemoveDevice(endpointId)) {
		shell_fprintf(shell, SHELL_INFO, "Done\n");
	}
#else
	if (CHIP_NO_ERROR == SimulatedBridgedDeviceFactory::RemoveDevice(endpointId)) {
		shell_fprintf(shell, SHELL_INFO, "Done\n");
	}
#endif
	else {
		shell_fprintf(shell, SHELL_ERROR, "Error: device remove failed\n");
	}
	return 0;
}

#ifdef CONFIG_BRIDGED_DEVICE_SIMULATED_ONOFF_SHELL
static int SimulatedBridgedDeviceOnOffWriteHandler(const struct shell *shell, size_t argc, char **argv)
{
	using DeviceType = Nrf::MatterBridgedDevice::DeviceType;
	const char *command = argv[0];
	uint8_t value = strtoul(argv[1], nullptr, 0);
	chip::EndpointId endpointId = strtoul(argv[2], nullptr, 0);

	uint16_t deviceType{};
	auto *provider = Nrf::BridgeManager().Instance().GetProvider(endpointId, deviceType);

	if (provider) {
		if ((0 == strcmp(command, "onoff") && deviceType != DeviceType::OnOffLight)) {
			shell_fprintf(shell, SHELL_ERROR, "Error: Unsupported device\n");
			return 0;
		}
		CHIP_ERROR err = provider->UpdateState(chip::app::Clusters::OnOff::Id,
						       chip::app::Clusters::OnOff::Attributes::OnOff::Id, &value);
		if (err != CHIP_NO_ERROR) {
			shell_fprintf(shell, SHELL_ERROR, "Cannot update OnOff device state\n");
			return 0;
		}
		shell_fprintf(shell, SHELL_INFO, "Done\n");

	} else {
		shell_fprintf(shell, SHELL_ERROR, "Error: Device inaccessible\n");
	}

	return 0;
}
#endif

#if defined(CONFIG_BRIDGED_DEVICE_SIMULATED) && defined(CONFIG_BRIDGE_ONOFF_LIGHT_SWITCH_BRIDGED_DEVICE)
static int SimulatedBridgedDeviceOnOffLightSwitchWriteHandler(const struct shell *shell, size_t argc, char **argv)
{
	using DeviceType = Nrf::MatterBridgedDevice::DeviceType;
	const char *command = argv[0];
	uint8_t value = strtoul(argv[1], nullptr, 0);
	chip::EndpointId endpointId = strtoul(argv[2], nullptr, 0);

	uint16_t deviceType{};
	auto *provider = Nrf::BridgeManager().Instance().GetProvider(endpointId, deviceType);

	if (provider) {
		if ((0 == strcmp(command, "onoff_switch") && deviceType != DeviceType::OnOffLightSwitch)) {
			shell_fprintf(shell, SHELL_ERROR, "Error: Unsupported device\n");
			return 0;
		}
		CHIP_ERROR err = provider->UpdateState(chip::app::Clusters::OnOff::Id,
						       chip::app::Clusters::OnOff::Attributes::OnOff::Id, &value);
		if (err != CHIP_NO_ERROR) {
			shell_fprintf(shell, SHELL_ERROR, "Cannot update OnOff Light Switch device state\n");
			return 0;
		}
		shell_fprintf(shell, SHELL_INFO, "Done\n");

	} else {
		shell_fprintf(shell, SHELL_ERROR, "Error: Device inaccessible\n");
	}

	return 0;
}
#endif

#ifdef CONFIG_BRIDGED_DEVICE_BT
static void BluetoothScanResult(Nrf::BLEConnectivityManager::ScanResult &result, void *context)
{
	if (!result.mDevices || !context) {
		return;
	}

	const struct shell *shell = reinterpret_cast<struct shell *>(context);

	shell_fprintf(shell, SHELL_INFO, "Scan result:\n");
	shell_fprintf(shell, SHELL_INFO, "---------------------------------------------------------------------\n");
	shell_fprintf(shell, SHELL_INFO, "| Index |      Address      |                   UUID                 \n");
	shell_fprintf(shell, SHELL_INFO, "---------------------------------------------------------------------\n");
	for (int i = 0; i < result.mCount; i++) {
		shell_fprintf(shell, SHELL_INFO, "| %d     | %02x:%02x:%02x:%02x:%02x:%02x | 0x%04x (%s)\n", i,
			      result.mDevices[i].mAddr.a.val[5], result.mDevices[i].mAddr.a.val[4],
			      result.mDevices[i].mAddr.a.val[3], result.mDevices[i].mAddr.a.val[2],
			      result.mDevices[i].mAddr.a.val[1], result.mDevices[i].mAddr.a.val[0],
			      result.mDevices[i].mUuid,
			      BleBridgedDeviceFactory::GetUuidString(result.mDevices[i].mUuid));
	}
}

#ifdef CONFIG_BT_SMP
static int InsertBridgedDevicePincodeHandler(const struct shell *shell, size_t argc, char **argv)
{
	int bleDeviceIndex = strtoul(argv[1], NULL, 0);
	unsigned int pincode = strtoul(argv[2], NULL, 10);

	bt_addr_le_t address;
	if (Nrf::BLEConnectivityManager::Instance().GetScannedDeviceAddress(&address, bleDeviceIndex) !=
	    CHIP_NO_ERROR) {
		shell_fprintf(shell, SHELL_ERROR, "Invalid Bluetooth LE device index.\n");
	} else {
		shell_fprintf(shell, SHELL_ERROR, "Found device address\n");
	}

	Nrf::BLEConnectivityManager::Instance().SetPincode(address, pincode);
	return 0;
}
#endif /* CONFIG_BT_SMP */

static int ScanBridgedDeviceHandler(const struct shell *shell, size_t argc, char **argv)
{
	shell_fprintf(shell, SHELL_INFO, "Scanning for %d s ...\n", CONFIG_BRIDGE_BT_SCAN_TIMEOUT_MS / 1000);

	Nrf::BLEConnectivityManager::Instance().Scan(BluetoothScanResult, const_cast<struct shell *>(shell));

	return 0;
}
#endif /* CONFIG_BRIDGED_DEVICE_BT */

SHELL_STATIC_SUBCMD_SET_CREATE(
	sub_matter_bridge,
#ifdef CONFIG_BRIDGED_DEVICE_BT
	SHELL_CMD_ARG(add, NULL,
		      "Adds bridged device. \n"
		      "Usage: add <ble_device_index> [node_label]\n"
		      "* ble_device_index - the Bluetooth LE device's index on the list returned by the scan command\n"
		      "* node_label - the optional bridged device's node label\n",
		      AddBridgedDeviceHandler, 2, 1),
#else
	SHELL_CMD_ARG(
		add, NULL,
		"Adds bridged device. \n"
		"Usage: add <bridged_device_type> [node_label]\n"
		"* bridged_device_type - the bridged device's type, e.g. 15 - Generic Switch, 256 - OnOff Light, 259 - OnOff Light Switch, 770 - TemperatureSensor, 775 - HumiditySensor, \n"
		"* node_label - the optional bridged device's node label\n",
		AddBridgedDeviceHandler, 2, 1),
#endif /* CONFIG_BRIDGED_DEVICE_BT */
	SHELL_CMD_ARG(
		remove, NULL,
		"Removes bridged device. \n"
		"Usage: remove <bridged_device_endpoint_id>\n"
		"* bridged_device_endpoint_id - the bridged device's endpoint on which it was previously created\n",
		RemoveBridgedDeviceHandler, 2, 0),
#ifdef CONFIG_BRIDGED_DEVICE_SIMULATED_ONOFF_SHELL
	SHELL_CMD_ARG(
		onoff, NULL,
		"Changes the current state of the simulated onoff device. \n"
		"Usage: onoff <new_state> <bridged_device_endpoint_id>\n"
		"* new_state - new state of the simulated onoff device\n"
		"* bridged_device_endpoint_id - the bridged device's endpoint on which it was previously created\n",
		SimulatedBridgedDeviceOnOffWriteHandler, 3, 0),
#endif
#if defined(CONFIG_BRIDGED_DEVICE_SIMULATED) && defined(CONFIG_BRIDGE_ONOFF_LIGHT_SWITCH_BRIDGED_DEVICE)
	SHELL_CMD_ARG(
		onoff_switch, NULL,
		"Changes the current state of the simulated onoff light switch device. \n"
		"Usage: onoff_switch <new_state> <bridged_device_endpoint_id>\n"
		"* new_state - new state of the simulated onoff light switch device\n"
		"* bridged_device_endpoint_id - the bridged device's endpoint on which it was previously created\n",
		SimulatedBridgedDeviceOnOffLightSwitchWriteHandler, 3, 0),
#endif
#ifdef CONFIG_BRIDGED_DEVICE_BT
	SHELL_CMD_ARG(scan, NULL,
		      "Scan for Bluetooth LE devices to bridge. \n"
		      "Usage: scan\n",
		      ScanBridgedDeviceHandler, 1, 0),
#ifdef CONFIG_BT_SMP
	SHELL_CMD_ARG(pincode, NULL,
		      "Insert pincode for Bluetooth LE device pairing. \n"
		      "Usage: pincode <ble_device_index> <pincode>\n"
		      "* ble_device_index - the Bluetooth LE device's index on the list returned by the scan command\n"
		      "* pincode - is a pin required for Bluetooth LE pairing authentication\n",
		      InsertBridgedDevicePincodeHandler, 3, 0),
#endif /* CONFIG_BT_SMP */
#endif /* CONFIG_BRIDGED_DEVICE_BT */
	SHELL_SUBCMD_SET_END);

SHELL_CMD_REGISTER(matter_bridge, &sub_matter_bridge, "Matter bridge commands", NULL);
```

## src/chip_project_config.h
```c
/*
 * Copyright (c) 2023 Nordic Semiconductor ASA
 *
 * SPDX-License-Identifier: LicenseRef-Nordic-5-Clause
 */

/**
 *    @file
 *          Example project configuration file for CHIP.
 *
 *          This is a place to put application or project-specific overrides
 *          to the default configuration values for general CHIP features.
 *
 */

#pragma once

#define CHIP_CONFIG_LOG_MODULE_Zcl_PROGRESS 0
#define CHIP_CONFIG_LOG_MODULE_InteractionModel_PROGRESS 0
#define CHIP_CONFIG_LOG_MODULE_InteractionModel_DETAIL 0
#define CHIP_CONFIG_LOG_MODULE_DataManagement_PROGRESS 0
#define CHIP_CONFIG_LOG_MODULE_FabricProvisioning_PROGRESS 0
#define CHIP_CONFIG_LOG_MODULE_SecureChannel_PROGRESS 0

#define CHIP_DEVICE_CONFIG_DYNAMIC_ENDPOINT_COUNT CONFIG_BRIDGE_MAX_DYNAMIC_ENDPOINTS_NUMBER
```

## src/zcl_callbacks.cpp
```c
/*
 * Copyright (c) 2024 Nordic Semiconductor ASA
 *
 * SPDX-License-Identifier: LicenseRef-Nordic-5-Clause
 */

#ifdef CONFIG_BRIDGE_SMART_PLUG_SUPPORT
#include <lib/support/logging/CHIPLogging.h>

#include "app_task.h"

#include <app-common/zap-generated/attributes/Accessors.h>
#include <app-common/zap-generated/ids/Attributes.h>
#include <app-common/zap-generated/ids/Clusters.h>
#include <app/ConcreteAttributePath.h>

using namespace ::chip;
using namespace ::chip::app::Clusters;
using namespace ::chip::app::Clusters::OnOff;

void MatterPostAttributeChangeCallback(const chip::app::ConcreteAttributePath &attributePath, uint8_t type,
				       uint16_t size, uint8_t *value)
{
	if (attributePath.mClusterId == OnOff::Id && attributePath.mAttributeId == OnOff::Attributes::OnOff::Id &&
	    attributePath.mEndpointId == AppTask::Instance().kSmartplugEndpointId) {
		ChipLogProgress(Zcl, "Cluster OnOff: attribute OnOff set to %" PRIu8 "", *value);
		Nrf::GetBoard().GetLED(Nrf::DeviceLeds::LED2).Set(*value);
	}
}

void emberAfOnOffClusterInitCallback(EndpointId endpoint)
{
	if (endpoint == AppTask::Instance().kSmartplugEndpointId) {
		Protocols::InteractionModel::Status status;
		bool storedValue;
		/* Read storedValue on/off value */
		status = Attributes::OnOff::Get(endpoint, &storedValue);
		if (status == Protocols::InteractionModel::Status::Success) {
			/* Set actual state to the cluster state that was last persisted */
			Nrf::GetBoard().GetLED(Nrf::DeviceLeds::LED2).Set(storedValue);
		}
	}
}
#endif /* CONFIG_BRIDGE_SMART_PLUG_SUPPORT */
```
